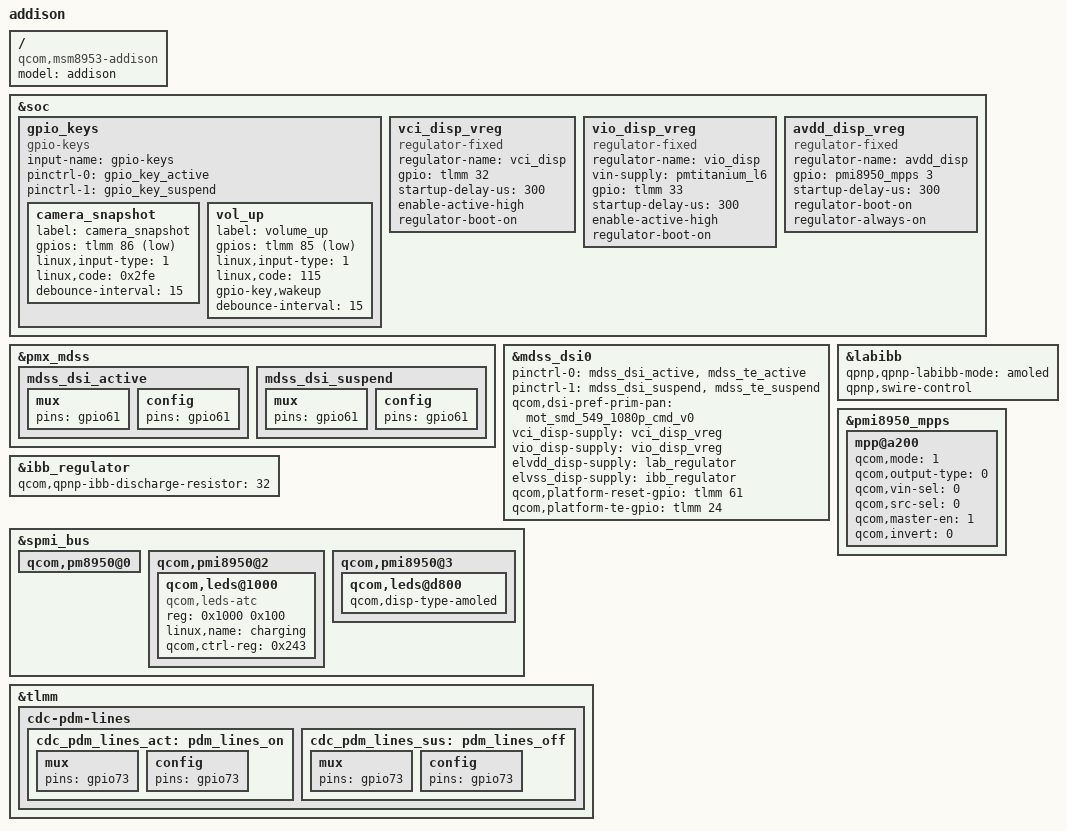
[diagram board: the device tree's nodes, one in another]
/* Copyright (c) 2016, Motorola Mobility Inc. All rights reserved.
 *
 * This program is free software; you can redistribute it and/or modify
 * it under the terms of the GNU General Public License version 2 and
 * only version 2 as published by the Free Software Foundation.
 *
 * This program is distributed in the hope that it will be useful,
 * but WITHOUT ANY WARRANTY; without even the implied warranty of
 * MERCHANTABILITY or FITNESS FOR A PARTICULAR PURPOSE.  See the
 * GNU General Public License for more details.
 */

#include "msm8953-moto-common.dtsi"
#include "dsi-panel-mot-smd-549-1080p-cmd.dtsi"

 / {
	model = "addison";
	compatible = "qcom,msm8953-addison", "qcom,msm8953-moto",
			"qcom,msmtitanium";
};

&soc {
	gpio_keys {
		compatible = "gpio-keys";
		input-name = "gpio-keys";
		pinctrl-names = "tlmm_gpio_key_active","tlmm_gpio_key_suspend";
		pinctrl-0 = <&gpio_key_active>;
		pinctrl-1 = <&gpio_key_suspend>;

		camera_snapshot {
			label = "camera_snapshot";
			gpios = <&tlmm 86 0x1>;
			linux,input-type = <1>;
			linux,code = <0x2fe>;
			debounce-interval = <15>;
		};

		vol_up {
			label = "volume_up";
			gpios = <&tlmm 85 0x1>;
			linux,input-type = <1>;
			linux,code = <115>;
			gpio-key,wakeup;
			debounce-interval = <15>;
		};
	};

	vci_disp_vreg: vci_disp_vreg {
		compatible = "regulator-fixed";
		regulator-name = "vci_disp";
		gpio = <&tlmm 32 0>;
		startup-delay-us = <300>;
		enable-active-high;
		regulator-boot-on;
	};

	vio_disp_vreg: vio_disp_vreg {
		compatible = "regulator-fixed";
		regulator-name = "vio_disp";
		vin-supply = <&pmtitanium_l6>;
		gpio = <&tlmm 33 0>;
		startup-delay-us = <300>;
		enable-active-high;
		regulator-boot-on;
	};

	avdd_disp_vreg: avdd_disp_vreg {
		compatible = "regulator-fixed";
		regulator-name = "avdd_disp";
		gpio = <&pmi8950_mpps 3 0>;
		startup-delay-us = <300>;
		regulator-boot-on;
		regulator-always-on;
	};
};

&pmx_mdss {
	mdss_dsi_active {
		mux {
			pins = "gpio61";
		};

		config {
			pins = "gpio61";
		};
	};

	mdss_dsi_suspend {
		mux {
			pins = "gpio61";
		};

		config {
			pins = "gpio61";
		};
	};
};

&mdss_dsi0 {
	pinctrl-names = "mdss_default", "mdss_sleep";
	pinctrl-0 = <&mdss_dsi_active &mdss_te_active>;
	pinctrl-1 = <&mdss_dsi_suspend &mdss_te_suspend>;

	qcom,dsi-pref-prim-pan = <&mot_smd_549_1080p_cmd_v0>;
	vci_disp-supply = <&vci_disp_vreg>;
	vio_disp-supply = <&vio_disp_vreg>;
	elvdd_disp-supply = <&lab_regulator>;
	elvss_disp-supply = <&ibb_regulator>;
	qcom,platform-reset-gpio = <&tlmm 61 0>;
	qcom,platform-te-gpio = <&tlmm 24 0>;
};

/* display boost and inverting boost regulators */
&labibb {
	status = "ok";
	qpnp,qpnp-labibb-mode = "amoled";
	qpnp,swire-control;
};

&ibb_regulator {
	qcom,qpnp-ibb-discharge-resistor = <32>;
};

&pmi8950_mpps {
	mpp@a200 {
		qcom,mode = <1>;		/* Digital output */
		qcom,output-type = <0>;		/* CMOS logic */
		qcom,vin-sel = <0>;
		qcom,src-sel = <0>;		/* Constant */
		qcom,master-en = <1>;		/* Enable GPIO */
		qcom,invert = <0>;
		status = "okay";
	};
};

&spmi_bus {
	qcom,pm8950@0 {
		/delete-node/ qcom,leds@a300;
	};

	qcom,pmi8950@2 {
		/delete-node/ qcom,leds@a100;

		qcom,leds@1000 {
			status = "ok";
			reg = <0x1000 0x100>;
			compatible = "qcom,leds-atc";
			linux,name = "charging";
			qcom,ctrl-reg = <0x243>;
		};
	};

	qcom,pmi8950@3 {
		qcom,leds@d800 {
			qcom,disp-type-amoled;
		};
	};
};

&tlmm {
	cdc-pdm-lines {
		cdc_pdm_lines_act: pdm_lines_on {
			mux {
				/delete-property/ pins;
				pins = "gpio73";
			};

			config {
				/delete-property/ pins;
				pins = "gpio73";
			};
		};

		cdc_pdm_lines_sus: pdm_lines_off {
			mux {
				/delete-property/ pins;
				pins = "gpio73";
			};

			config {
				/delete-property/ pins;
				pins = "gpio73";
			};
		};
	};
};
